AUTOSAR XML (schema 4-3-0)
package /model
  composition sw component type RootComposition
    4 x component:
      Application{1..4}: type=ApplicationType{1..4}
    connect Application1.Sender -> Application{2..4}.Receiver
    connect Application2.Sender2 -> Application1.Receiver2
package /Applications
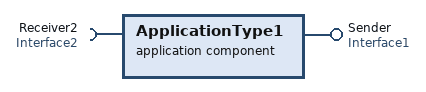
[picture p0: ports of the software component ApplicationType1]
  application sw component type ApplicationType1
    provide port Sender: provided-interface=Interface1
    require port Receiver2: required-interface=Interface2
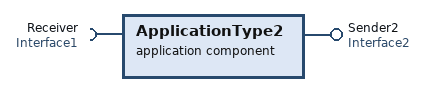
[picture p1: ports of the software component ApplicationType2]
  application sw component type ApplicationType2
    require port Receiver: required-interface=Interface1
    provide port Sender2: provided-interface=Interface2
  application sw component type ApplicationType3
    require port Receiver: required-interface=Interface1
  application sw component type ApplicationType4
    require port Receiver: required-interface=Interface1
package /Interfaces
  sender receiver interface Interface1
  sender receiver interface Interface2
